# msp430fr5739 register map
Registers are 16-bit, access not given, no defined reset value unless marked. A register's access mark holds for its fields unless they carry their own. Addresses are absolute; registers are grouped by the start of their names; [hi:lo] are bit positions; {n}, {i} and the like mark numbered series; 'fields as' and 'values as' point back to an identical list.

## SFR
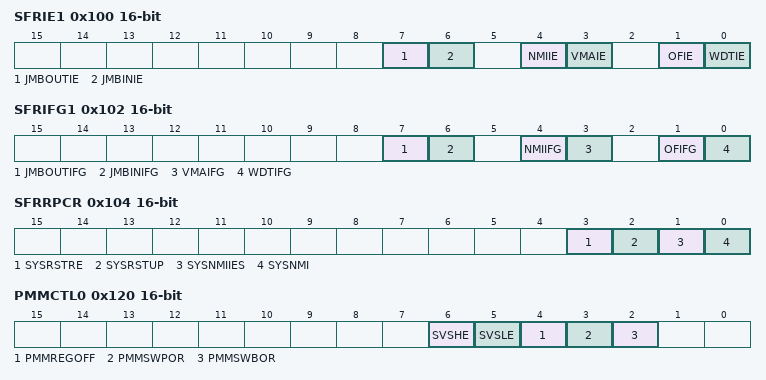
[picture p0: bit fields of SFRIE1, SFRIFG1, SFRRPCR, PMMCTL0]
0x100 SFRIE1
  [7] JMBOUTIE, [6] JMBINIE, [4] NMIIE, [3] VMAIE, [1] OFIE, [0] WDTIE
0x102 SFRIFG1
  [7] JMBOUTIFG, [6] JMBINIFG, [4] NMIIFG, [3] VMAIFG, [1] OFIFG, [0] WDTIFG
0x104 SFRRPCR
  [3] SYSRSTRE, [2] SYSRSTUP, [1] SYSNMIIES, [0] SYSNMI
0x120 PMMCTL0
  [6] SVSHE, [5] SVSLE, [4] PMMREGOFF, [3] PMMSWPOR, [2] PMMSWBOR
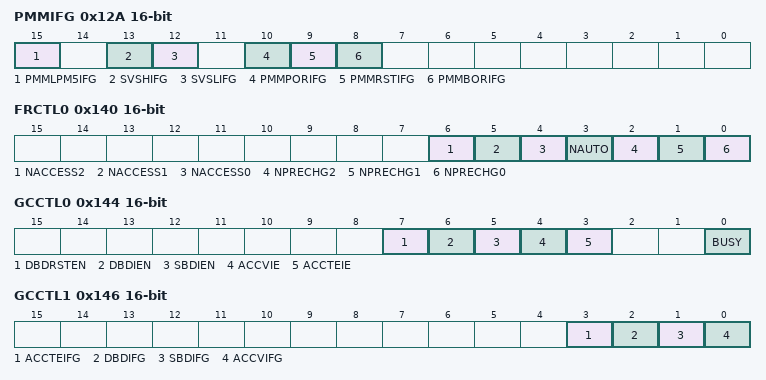
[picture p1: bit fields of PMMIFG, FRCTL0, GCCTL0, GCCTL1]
0x12A PMMIFG
  [15] PMMLPM5IFG, [13] SVSHIFG, [12] SVSLIFG, [10] PMMPORIFG, [9] PMMRSTIFG, [8] PMMBORIFG
0x130 PM5CTL0
  [0] LOCKLPM5
0x140 FRCTL0
  [6] NACCESS2, [5] NACCESS1, [4] NACCESS0, [3] NAUTO, [2] NPRECHG2, [1] NPRECHG1, [0] NPRECHG0
0x144 GCCTL0
  [7] DBDRSTEN, [6] DBDIEN, [5] SBDIEN, [4] ACCVIE, [3] ACCTEIE, [0] BUSY
0x146 GCCTL1
  [3] ACCTEIFG, [2] DBDIFG, [1] SBDIFG, [0] ACCVIFG
0x150 CRCDI
0x152 CRCDIRB
0x154 CRCINIRES
0x156 CRCRESR
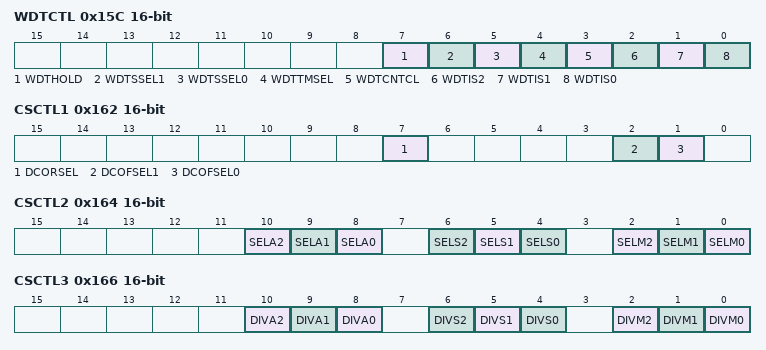
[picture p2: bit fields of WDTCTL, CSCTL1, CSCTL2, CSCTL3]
0x15C WDTCTL
  [7] WDTHOLD, [6] WDTSSEL1, [5] WDTSSEL0, [4] WDTTMSEL, [3] WDTCNTCL, [2] WDTIS2, [1] WDTIS1, [0] WDTIS0
0x160 CSCTL0
0x162 CSCTL1
  [7] DCORSEL, [2] DCOFSEL1, [1] DCOFSEL0
0x164 CSCTL2
  [10] SELA2, [9] SELA1, [8] SELA0, [6] SELS2, [5] SELS1, [4] SELS0, [2] SELM2, [1] SELM1, [0] SELM0
0x166 CSCTL3
  [10] DIVA2, [9] DIVA1, [8] DIVA0, [6] DIVS2, [5] DIVS1, [4] DIVS0, [2] DIVM2, [1] DIVM1, [0] DIVM0
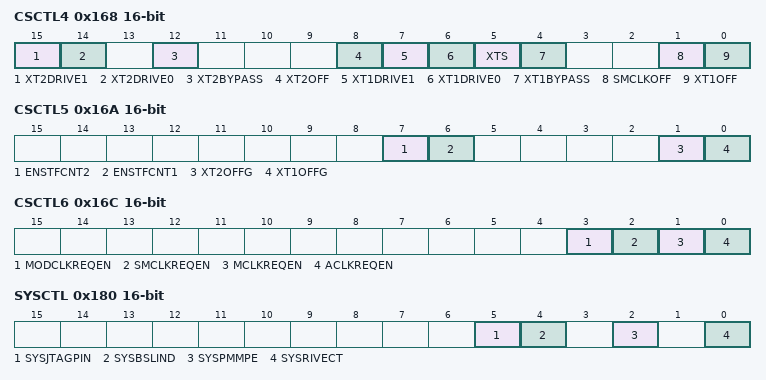
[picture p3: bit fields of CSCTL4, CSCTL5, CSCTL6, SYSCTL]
0x168 CSCTL4
  [15] XT2DRIVE1, [14] XT2DRIVE0, [12] XT2BYPASS, [8] XT2OFF, [7] XT1DRIVE1, [6] XT1DRIVE0, [5] XTS, [4] XT1BYPASS, [1] SMCLKOFF, [0] XT1OFF
0x16A CSCTL5
  [7] ENSTFCNT2, [6] ENSTFCNT1, [1] XT2OFFG, [0] XT1OFFG
0x16C CSCTL6
  [3] MODCLKREQEN, [2] SMCLKREQEN, [1] MCLKREQEN, [0] ACLKREQEN
0x180 SYSCTL
  [5] SYSJTAGPIN, [4] SYSBSLIND, [2] SYSPMMPE, [0] SYSRIVECT
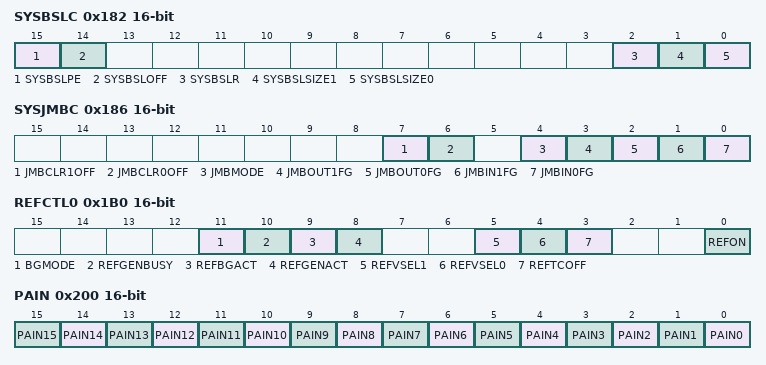
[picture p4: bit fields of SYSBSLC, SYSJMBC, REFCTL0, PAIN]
0x182 SYSBSLC
  [15] SYSBSLPE, [14] SYSBSLOFF, [2] SYSBSLR, [1] SYSBSLSIZE1, [0] SYSBSLSIZE0
0x186 SYSJMBC
  [7] JMBCLR1OFF, [6] JMBCLR0OFF, [4] JMBMODE, [3] JMBOUT1FG, [2] JMBOUT0FG, [1] JMBIN1FG, [0] JMBIN0FG
0x188 SYSJMBI0
0x18A SYSJMBI1
0x18C SYSJMBO0
0x18E SYSJMBO1
0x198 SYSBERRIV
0x19A SYSUNIV
0x19C SYSSNIV
0x19E SYSRSTIV
0x1B0 REFCTL0
  [11] BGMODE, [10] REFGENBUSY, [9] REFBGACT, [8] REFGENACT, [5] REFVSEL1, [4] REFVSEL0, [3] REFTCOFF, [0] REFON
0x200 PAIN
  [n] PAIN{n} (n=0..15)
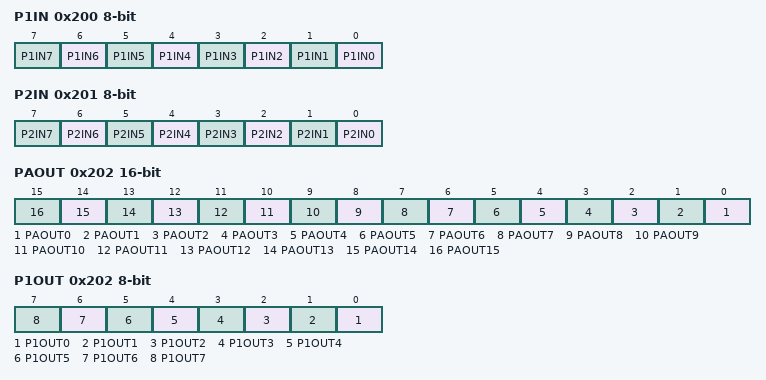
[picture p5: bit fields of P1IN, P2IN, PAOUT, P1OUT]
0x200 P1IN 8-bit
  [n] P1IN{n} (n=0..7)
0x201 P2IN 8-bit
  [n] P2IN{n} (n=0..7)
0x202 PAOUT
  [n] PAOUT{n} (n=0..15)
0x202 P1OUT 8-bit
  [n] P1OUT{n} (n=0..7)
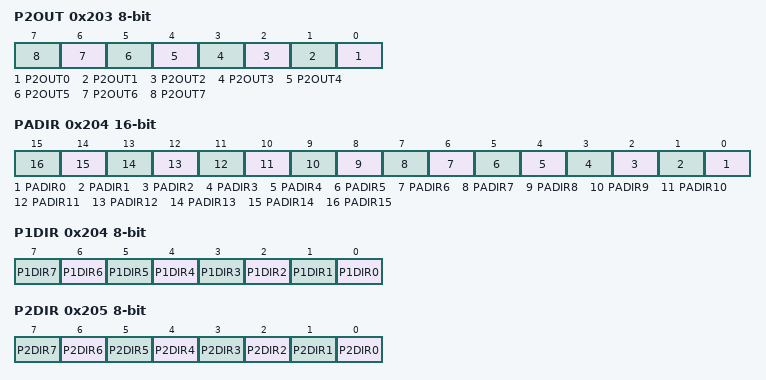
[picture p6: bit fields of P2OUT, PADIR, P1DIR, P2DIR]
0x203 P2OUT 8-bit
  [n] P2OUT{n} (n=0..7)
0x204 PADIR
  [n] PADIR{n} (n=0..15)
0x204 P1DIR 8-bit
  [n] P1DIR{n} (n=0..7)
0x205 P2DIR 8-bit
  [n] P2DIR{n} (n=0..7)
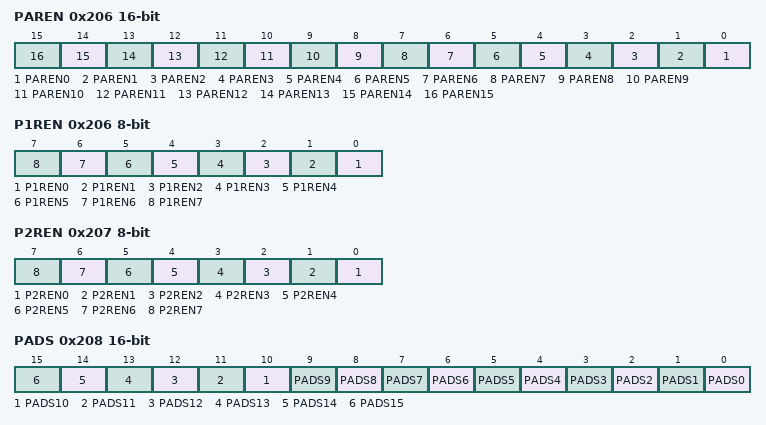
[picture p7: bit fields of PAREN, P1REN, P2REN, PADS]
0x206 PAREN
  [n] PAREN{n} (n=0..15)
0x206 P1REN 8-bit
  [n] P1REN{n} (n=0..7)
0x207 P2REN 8-bit
  [n] P2REN{n} (n=0..7)
0x208 PADS
  [n] PADS{n} (n=0..15)
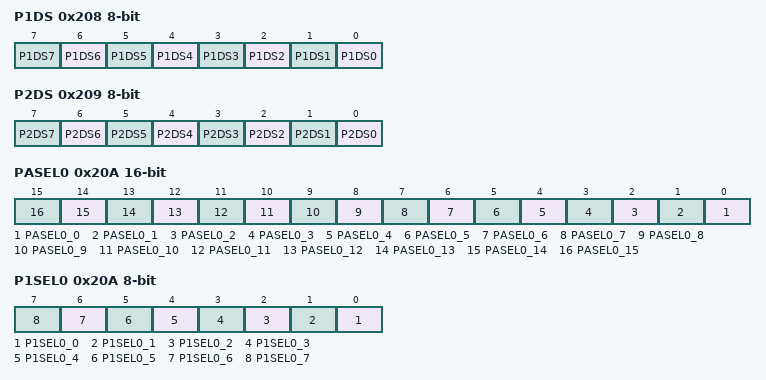
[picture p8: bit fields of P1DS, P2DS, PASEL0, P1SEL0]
0x208 P1DS 8-bit
  [n] P1DS{n} (n=0..7)
0x209 P2DS 8-bit
  [n] P2DS{n} (n=0..7)
0x20A PASEL0
  [n] PASEL0_{n} (n=0..15)
0x20A P1SEL0 8-bit
  [n] P1SEL0_{n} (n=0..7)
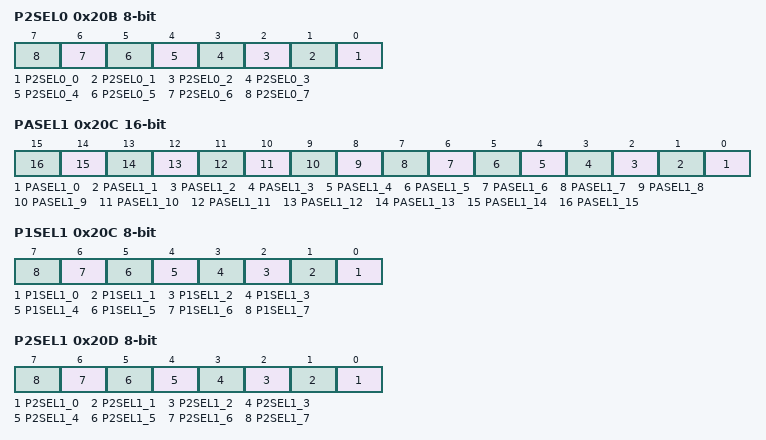
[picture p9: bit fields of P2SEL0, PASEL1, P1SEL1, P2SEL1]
0x20B P2SEL0 8-bit
  [n] P2SEL0_{n} (n=0..7)
0x20C PASEL1
  [n] PASEL1_{n} (n=0..15)
0x20C P1SEL1 8-bit
  [n] P1SEL1_{n} (n=0..7)
0x20D P2SEL1 8-bit
  [n] P2SEL1_{n} (n=0..7)
{0x1FE+0x10*i} P{i}IV (i=1..4)
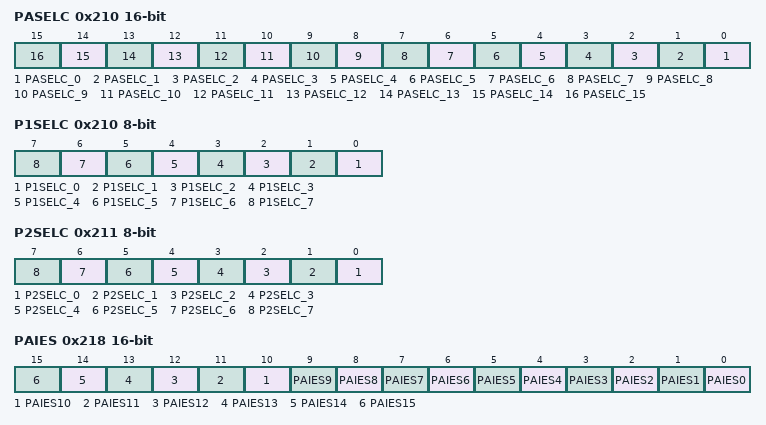
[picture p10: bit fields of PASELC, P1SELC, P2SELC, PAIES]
0x210 PASELC
  [n] PASELC_{n} (n=0..15)
0x210 P1SELC 8-bit
  [n] P1SELC_{n} (n=0..7)
0x211 P2SELC 8-bit
  [n] P2SELC_{n} (n=0..7)
0x218 PAIES
  [n] PAIES{n} (n=0..15)
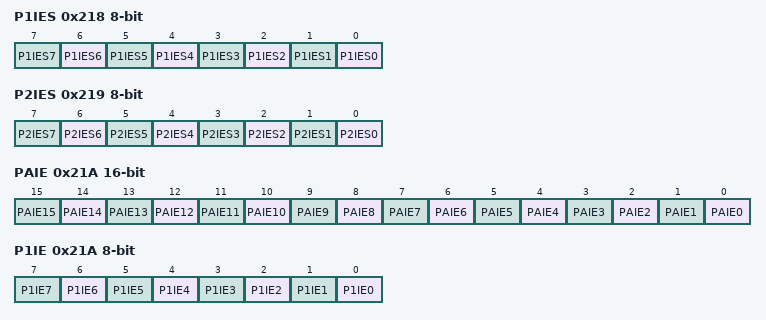
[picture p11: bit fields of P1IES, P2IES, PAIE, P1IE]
0x218 P1IES 8-bit
  [n] P1IES{n} (n=0..7)
0x219 P2IES 8-bit
  [n] P2IES{n} (n=0..7)
0x21A PAIE
  [n] PAIE{n} (n=0..15)
0x21A P1IE 8-bit
  [n] P1IE{n} (n=0..7)
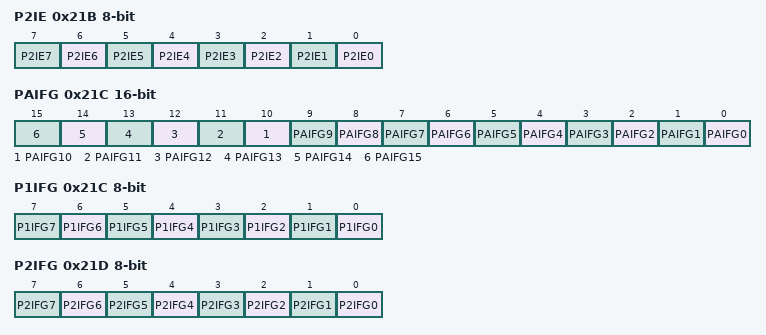
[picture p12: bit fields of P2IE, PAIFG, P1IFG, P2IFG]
0x21B P2IE 8-bit
  [n] P2IE{n} (n=0..7)
0x21C PAIFG
  [n] PAIFG{n} (n=0..15)
0x21C P1IFG 8-bit
  [n] P1IFG{n} (n=0..7)
0x21D P2IFG 8-bit
  [n] P2IFG{n} (n=0..7)
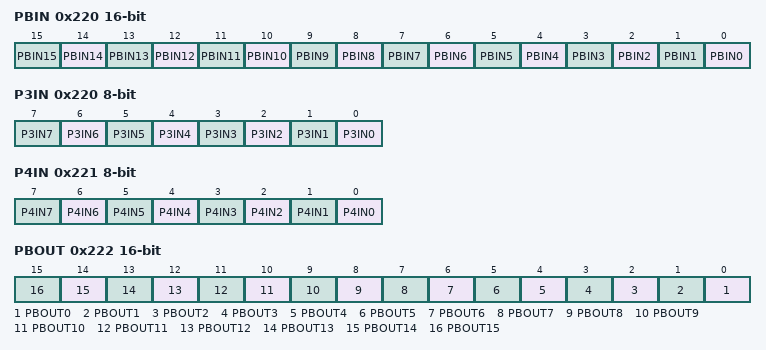
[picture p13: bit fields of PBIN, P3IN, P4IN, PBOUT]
0x220 PBIN
  [n] PBIN{n} (n=0..15)
0x220 P3IN 8-bit
  [n] P3IN{n} (n=0..7)
0x221 P4IN 8-bit
  [n] P4IN{n} (n=0..7)
0x222 PBOUT
  [n] PBOUT{n} (n=0..15)
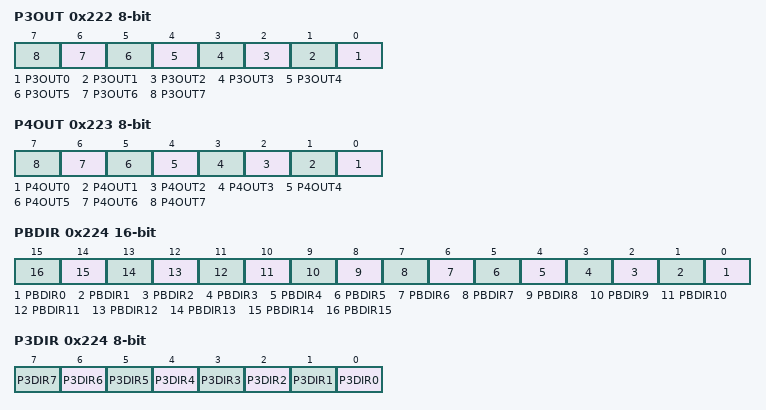
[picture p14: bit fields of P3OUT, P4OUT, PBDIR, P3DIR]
0x222 P3OUT 8-bit
  [n] P3OUT{n} (n=0..7)
0x223 P4OUT 8-bit
  [n] P4OUT{n} (n=0..7)
0x224 PBDIR
  [n] PBDIR{n} (n=0..15)
0x224 P3DIR 8-bit
  [n] P3DIR{n} (n=0..7)
0x225 P4DIR 8-bit
  [n] P4DIR{n} (n=0..7)
0x226 PBREN
  [n] PBREN{n} (n=0..15)
0x226 P3REN 8-bit
  [n] P3REN{n} (n=0..7)
0x227 P4REN 8-bit
  [n] P4REN{n} (n=0..7)
0x228 PBDS
  [n] PBDS{n} (n=0..15)
0x228 P3DS 8-bit
  [n] P3DS{n} (n=0..7)
0x229 P4DS 8-bit
  [n] P4DS{n} (n=0..7)
0x22A PBSEL0
  [n] PBSEL0_{n} (n=0..15)
0x22A P3SEL0 8-bit
  [n] P3SEL0_{n} (n=0..7)
0x22B P4SEL0 8-bit
  [n] P4SEL0_{n} (n=0..7)
0x22C PBSEL1
  [n] PBSEL1_{n} (n=0..15)
0x22C P3SEL1 8-bit
  [n] P3SEL1_{n} (n=0..7)
0x22D P4SEL1 8-bit
  [n] P4SEL1_{n} (n=0..7)
0x230 PBSELC
  [n] PBSELC_{n} (n=0..15)
0x230 P3SELC 8-bit
  [n] P3SELC_{n} (n=0..7)
0x231 P4SELC 8-bit
  [n] P4SELC_{n} (n=0..7)
0x238 PBIES
  [n] PBIES{n} (n=0..15)
0x238 P3IES 8-bit
  [n] P3IES{n} (n=0..7)
0x239 P4IES 8-bit
  [n] P4IES{n} (n=0..7)
0x23A PBIE
  [n] PBIE{n} (n=0..15)
0x23A P3IE 8-bit
  [n] P3IE{n} (n=0..7)
0x23B P4IE 8-bit
  [n] P4IE{n} (n=0..7)
0x23C PBIFG
  [n] PBIFG{n} (n=0..15)
0x23C P3IFG 8-bit
  [n] P3IFG{n} (n=0..7)
0x23D P4IFG 8-bit
  [n] P4IFG{n} (n=0..7)
0x320 PJIN
  [n] PJIN{n} (n=0..5)
0x322 PJOUT
  [n] PJOUT{n} (n=0..5)
0x324 PJDIR
  [n] PJDIR{n} (n=0..5)
0x326 PJREN
  [n] PJREN{n} (n=0..5)
0x328 PJDS
  [n] PJDS{n} (n=0..5)
0x32A PJSEL0
  [n] PJSEL0_{n} (n=0..5)
0x32C PJSEL1
  [n] PJSEL1_{n} (n=0..5)
0x340 TA0CTL
  [9] TASSEL1, [8] TASSEL0, [7] ID1, [6] ID0, [5] MC1, [4] MC0, [2] TACLR, [1] TAIE, [0] TAIFG
{0x342+2i} TA0CCTL{i} (i=0..2)
  [15] CM1, [14] CM0, [13] CCIS1, [12] CCIS0, [11] SCS, [10] SCCI, [8] CAP, [7] OUTMOD2, [6] OUTMOD1, [5] OUTMOD0, [4] CCIE, [3] CCI, [2] OUT, [1] COV, [0] CCIFG
0x350 TA0R
{0x352+2i} TA0CCR{i} (i=0..2)
0x360 TA0EX0
  [2] TAIDEX2, [1] TAIDEX1, [0] TAIDEX0
0x36E TA0IV
0x380 TA1CTL
  fields as TA0CTL
{0x382+2i} TA1CCTL{i} (i=0..2)
  fields as TA0CCTL0
0x390 TA1R
{0x392+2i} TA1CCR{i} (i=0..2)
0x3A0 TA1EX0
  [2] TAIDEX2, [1] TAIDEX1, [0] TAIDEX0
0x3AE TA1IV
{0x3C0+0x40*i} TB{i}CTL (i=0..2)
  [14] TBCLGRP1, [13] TBCLGRP0, [12] CNTL1, [11] CNTL0, [9] TBSSEL1, [8] TBSSEL0, [7] ID1, [6] ID0, [5] MC1, [4] MC0, [2] TBCLR, [1] TBIE, [0] TBIFG
{0x3C2+0x40*i} TB{i}CCTL0 (i=0..2)
  [15] CM1, [14] CM0, [13] CCIS1, [12] CCIS0, [11] SCS, [10] CLLD1, [9] CLLD0, [8] CAP, [7] OUTMOD2, [6] OUTMOD1, [5] OUTMOD0, [4] CCIE, [3] CCI, [2] OUT, [1] COV, [0] CCIFG
{0x3C4+0x40*i} TB{i}CCTL1 (i=0..2)
  fields as TB0CCTL0
{0x3C6+0x40*i} TB{i}CCTL2 (i=0..2)
  fields as TB0CCTL0
{0x3D0+0x40*i} TB{i}R (i=0..2)
{0x3D2+0x40*i} TB{i}CCR0 (i=0..2)
{0x3D4+0x40*i} TB{i}CCR1 (i=0..2)
{0x3D6+0x40*i} TB{i}CCR2 (i=0..2)
0x3E0 TB0EX0
  [2] TBIDEX2, [1] TBIDEX1, [0] TBIDEX0
{0x3EE+0x40*i} TB{i}IV (i=0..2)
0x420 TB1EX0
  [2] TBIDEX2, [1] TBIDEX1, [0] TBIDEX0
0x460 TB2EX0
0x4A0 RTCCTL01
  [15] RTCBCD, [14] RTCHOLD, [12] RTCRDY, [9] RTCTEV1, [8] RTCTEV0, [7] RTCOFIE, [6] RTCTEVIE, [5] RTCAIE, [4] RTCRDYIE, [3] RTCOFIFG, [2] RTCTEVIFG, [1] RTCAIFG, [0] RTCRDYIFG
0x4A2 RTCCTL23
  [9] RTCCALF1, [8] RTCCALF0, [7] RTCCALS, [n] RTCCAL{n} (n=0..5)
0x4A8 RTCPS0CTL
  [4] RT0IP2, [3] RT0IP1, [2] RT0IP0, [1] RT0PSIE, [0] RT0PSIFG
0x4AA RTCPS1CTL
  [4] RT1IP2, [3] RT1IP1, [2] RT1IP0, [1] RT1PSIE, [0] RT1PSIFG
0x4AC RTCPS
0x4AE RTCIV
0x4B0 RTCTIM0
0x4B2 RTCTIM1
0x4B4 RTCDATE
0x4B6 RTCYEAR
0x4B8 RTCAMINHR
0x4BA RTCADOWDAY
0x4BC BIN2BCD
0x4BE BCD2BIN
0x4C0 MPY
0x4C2 MPYS
0x4C4 MAC
0x4C6 MACS
0x4C8 OP2
0x4CA RESLO
0x4CC RESHI
0x4CE SUMEXT
0x4D0 MPY32L
0x4D2 MPY32H
0x4D4 MPYS32L
0x4D6 MPYS32H
0x4D8 MAC32L
0x4DA MAC32H
0x4DC MACS32L
0x4DE MACS32H
0x4E0 OP2L
0x4E2 OP2H
{0x4E4+2i} RES{i} (i=0..3)
0x4EC MPY32CTL0
  [9] MPYDLY32, [8] MPYDLYWRTEN, [7] OP2_32, [6] OP1_32, [5] MPYM1, [4] MPYM0, [3] MPYSAT, [2] MPYFRAC, [0] MPYC
0x500 DMACTL0
  [n+8] DMA1TSEL{n} (n=0..4), [n] DMA0TSEL{n} (n=0..4)
0x502 DMACTL1
  [n] DMA2TSEL{n} (n=0..4)
0x504 DMACTL2
0x506 DMACTL3
0x508 DMACTL4
  [2] DMARMWDIS, [1] ROUNDROBIN, [0] ENNMI
0x50E DMAIV
{0x510+0x10*i} DMA{i}CTL (i=0..2)
  [14] DMADT2, [13] DMADT1, [12] DMADT0, [11] DMADSTINCR1, [10] DMADSTINCR0, [9] DMASRCINCR1, [8] DMASRCINCR0, [7] DMADSTBYTE, [6] DMASRCBYTE, [5] DMALEVEL, [4] DMAEN, [3] DMAIFG, [2] DMAIE, [1] DMAABORT, [0] DMAREQ
{0x512+0x10*i} DMA{i}SA 32-bit (i=0..2)
{0x516+0x10*i} DMA{i}DA 32-bit (i=0..2)
{0x51A+0x10*i} DMA{i}SZ (i=0..2)
0x5A0 MPUCTL0
  [4] MPUSEGIE, [1] MPULOCK, [0] MPUENA
0x5A2 MPUCTL1
  [3] MPUSEGIIFG, [2] MPUSEG3IFG, [1] MPUSEG2IFG, [0] MPUSEG1IFG
0x5A4 MPUSEG
  [n-12] MPUSB{n} (n=20..24), [n-10] MPUSB{n} (n=10..14)
0x5A6 MPUSAM
  [15] MPUSEGIVS, [14] MPUSEGIXE, [13] MPUSEGIWE, [12] MPUSEGIRE, [11] MPUSEG3VS, [10] MPUSEG3XE, [9] MPUSEG3WE, [8] MPUSEG3RE, [7] MPUSEG2VS, [6] MPUSEG2XE, [5] MPUSEG2WE, [4] MPUSEG2RE, [3] MPUSEG1VS, [2] MPUSEG1XE, [1] MPUSEG1WE, [0] MPUSEG1RE
0x5C0 UCA0CTLW0
  [15] UCPEN, [14] UCPAR, [13] UCMSB, [12] UC7BIT, [11] UCSPB, [10] UCMODE1, [9] UCMODE0, [8] UCSYNC, [7] UCSSEL1, [6] UCSSEL0, [5] UCRXEIE, [4] UCBRKIE, [3] UCDORM, [2] UCTXADDR, [1] UCTXBRK, [0] UCSWRST
0x5C0 UCA0CTL1 8-bit
0x5C0 UCA0CTLW0__SPI
  [15] UCCKPH, [14] UCCKPL, [13] UCMSB, [12] UC7BIT, [11] UCMST, [10] UCMODE1, [9] UCMODE0, [8] UCSYNC, [7] UCSSEL1, [6] UCSSEL0, [1] UCSTEM, [0] UCSWRST
0x5C0 UCA0CTL1__SPI 8-bit
0x5C1 UCA0CTL0 8-bit
0x5C1 UCA0CTL0__SPI 8-bit
0x5C2 UCA0CTLW1
  [1] UCGLIT1, [0] UCGLIT0
0x5C6 UCA0BRW
0x5C6 UCA0BR0 8-bit
0x5C6 UCA0BRW__SPI
0x5C6 UCA0BR0__SPI 8-bit
0x5C7 UCA0BR1 8-bit
0x5C7 UCA0BR1__SPI 8-bit
0x5C8 UCA0MCTLW
  [n+8] UCBRS{n} (n=0..7), [n+4] UCBRF{n} (n=0..3), [0] UCOS16
0x5CA UCA0STATW 8-bit
  [7] UCLISTEN, [6] UCFE, [5] UCOE, [4] UCPE, [3] UCBRK, [2] UCRXERR, [1] UCADDR, [0] UCBUSY
0x5CA UCA0STATW__SPI 8-bit
  [7] UCLISTEN, [6] UCFE, [5] UCOE, [0] UCBUSY
0x5CC UCA0RXBUF
0x5CC UCA0RXBUF__SPI
0x5CE UCA0TXBUF
0x5CE UCA0TXBUF__SPI
0x5D0 UCA0ABCTL 8-bit
  [5] UCDELIM1, [4] UCDELIM0, [3] UCSTOE, [2] UCBTOE, [0] UCABDEN
0x5D2 UCA0IRCTL
  [n+10] UCIRRXFL{n} (n=0..5), [9] UCIRRXPL, [8] UCIRRXFE, [n+2] UCIRTXPL{n} (n=0..5), [1] UCIRTXCLK, [0] UCIREN
0x5D2 UCA0IRTCTL 8-bit
0x5D3 UCA0IRRCTL 8-bit
0x5DA UCA0IE
0x5DC UCA0IFG
0x5DE UCA0IV
0x5DE UCA0IV__SPI
0x5E0 UCA1CTLW0
  fields as UCA0CTLW0
0x5E0 UCA1CTL1 8-bit
0x5E0 UCA1CTLW0__SPI
  fields as UCA0CTLW0__SPI
0x5E0 UCA1CTL1__SPI 8-bit
0x5E1 UCA1CTL0 8-bit
0x5E1 UCA1CTL0__SPI 8-bit
0x5E2 UCA1CTLW1
  [1] UCGLIT1, [0] UCGLIT0
0x5E6 UCA1BRW
0x5E6 UCA1BR0 8-bit
0x5E6 UCA1BRW__SPI
0x5E6 UCA1BR0__SPI 8-bit
0x5E7 UCA1BR1 8-bit
0x5E7 UCA1BR1__SPI 8-bit
0x5E8 UCA1MCTLW
  [n+8] UCBRS{n} (n=0..7), [n+4] UCBRF{n} (n=0..3), [0] UCOS16
0x5EA UCA1STATW 8-bit
  fields as UCA0STATW
0x5EA UCA1STATW__SPI 8-bit
  [7] UCLISTEN, [6] UCFE, [5] UCOE, [0] UCBUSY
0x5EC UCA1RXBUF
0x5EC UCA1RXBUF__SPI
0x5EE UCA1TXBUF
0x5EE UCA1TXBUF__SPI
0x5F0 UCA1ABCTL 8-bit
  [5] UCDELIM1, [4] UCDELIM0, [3] UCSTOE, [2] UCBTOE, [0] UCABDEN
0x5F2 UCA1IRCTL
  fields as UCA0IRCTL
0x5F2 UCA1IRTCTL 8-bit
0x5F3 UCA1IRRCTL 8-bit
0x5FA UCA1IE
0x5FC UCA1IFG
0x5FE UCA1IV
0x5FE UCA1IV__SPI
0x640 UCB0CTLW0
  [15] UCA10, [14] UCSLA10, [13] UCMM, [11] UCMST, [10] UCMODE1, [9] UCMODE0, [7] UCSSEL1, [6] UCSSEL0, [5] UCTXACK, [4] UCTR, [3] UCTXNACK, [2] UCTXSTP, [1] UCTXSTT, [0] UCSWRST
0x640 UCB0CTL1 8-bit
0x640 UCB0CTLW0__SPI
  fields as UCA0CTLW0__SPI
0x640 UCB0CTL1__SPI 8-bit
0x641 UCB0CTL0 8-bit
0x641 UCB0CTL0__SPI 8-bit
0x642 UCB0CTLW1
  [8] UCETXINT, [7] UCCLTO1, [6] UCCLTO0, [5] UCSTPNACK, [4] UCSWACK, [3] UCASTP1, [2] UCASTP0, [1] UCGLIT1, [0] UCGLIT0
0x646 UCB0BRW
0x646 UCB0BR0 8-bit
0x646 UCB0BRW__SPI
0x646 UCB0BR0__SPI 8-bit
0x647 UCB0BR1 8-bit
0x647 UCB0BR1__SPI 8-bit
0x648 UCB0STATW
0x649 UCB0BCNT__I2C 8-bit
0x64A UCB0TBCNT
0x64C UCB0RXBUF
0x64C UCB0RXBUF__SPI
0x64E UCB0TXBUF
0x64E UCB0TXBUF__SPI
0x654 UCB0I2COA0
  [15] UCGCEN, [10] UCOAEN, [n] UCOA{n} (n=0..9)
{0x654+2i} UCB0I2COA{i} (i=1..3)
  [10] UCOAEN, [n] UCOA{n} (n=0..9)
0x65C UCB0ADDRX
  [n] UCADDRX{n} (n=0..9)
0x65E UCB0ADDMASK
  [n] UCADDMASK{n} (n=0..9)
0x660 UCB0I2CSA
  [n] UCSA{n} (n=0..9)
0x66A UCB0IE
0x66C UCB0IFG
0x66E UCB0IV
0x66E UCB0IV__SPI
0x700 ADC10CTL0
  [n+8] ADC10SHT{n} (n=0..3), [7] ADC10MSC, [4] ADC10ON, [1] ADC10ENC, [0] ADC10SC
0x702 ADC10CTL1
  [11] ADC10SHS1, [10] ADC10SHS0, [9] ADC10SHP, [8] ADC10ISSH, [7] ADC10DIV2, [6] ADC10DIV1, [5] ADC10DIV0, [4] ADC10SSEL1, [3] ADC10SSEL0, [2] ADC10CONSEQ1, [1] ADC10CONSEQ0, [0] ADC10BUSY
0x704 ADC10CTL2
  [9] ADC10PDIV1, [8] ADC10PDIV0, [4] ADC10RES, [3] ADC10DF, [2] ADC10SR, [0] ADC10REFBURST
0x706 ADC10LO
0x708 ADC10HI
0x70A ADC10MCTL0
  [6] ADC10SREF2, [5] ADC10SREF1, [4] ADC10SREF0, [n] ADC10INCH{n} (n=0..3)
0x712 ADC10MEM0
0x71A ADC10IE
  [5] ADC10TOVIE, [4] ADC10OVIE, [3] ADC10HIIE, [2] ADC10LOIE, [1] ADC10INIE, [0] ADC10IE0
0x71C ADC10IFG
  [5] ADC10TOVIFG, [4] ADC10OVIFG, [3] ADC10HIIFG, [2] ADC10LOIFG, [1] ADC10INIFG, [0] ADC10IFG0
0x71E ADC10IV
0x8C0 CDCTL0
  [15] CDIMEN, [n+8] CDIMSEL{n} (n=0..3), [7] CDIPEN, [n] CDIPSEL{n} (n=0..3)
0x8C2 CDCTL1
  [12] CDMRVS, [11] CDMRVL, [10] CDON, [7] CDFDLY1, [6] CDFDLY0, [5] CDEX, [4] CDSHORT, [3] CDIES, [2] CDF, [1] CDOUTPOL, [0] CDOUT
0x8C4 CDCTL2
  [15] CDREFACC, [14] CDREFL1, [13] CDREFL0, [n-2] CDREF{n} (n=10..14), [7] CDRS1, [6] CDRS0, [5] CDRSEL, [n] CDREF{n:02} (n=0..4)
0x8C6 CDCTL3
  [n] CDPD{n} (n=0..15)
0x8CC CDINT
  [9] CDIIE, [8] CDIE, [1] CDIIFG, [0] CDIFG
0x8CE CDIV
